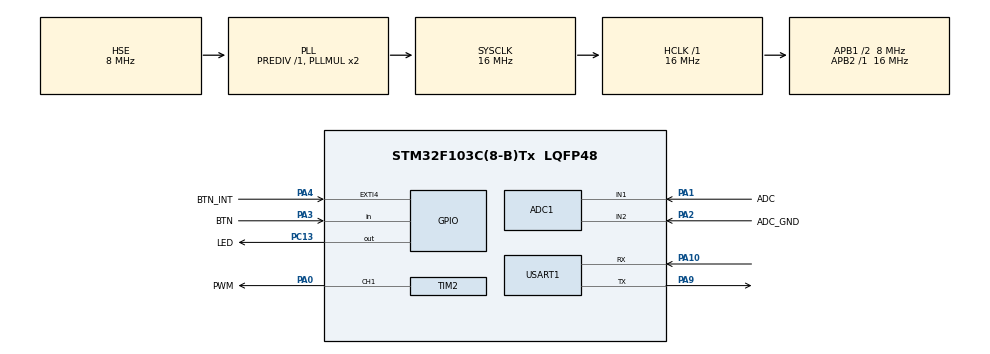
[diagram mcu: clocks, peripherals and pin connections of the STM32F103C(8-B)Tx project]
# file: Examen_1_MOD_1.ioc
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ADC1.Channel-0\#ChannelRegularConversion=ADC_CHANNEL_1
ADC1.NbrOfConversionFlag=1
ADC1.Rank-0\#ChannelRegularConversion=1
ADC1.SamplingTime-0\#ChannelRegularConversion=ADC_SAMPLETIME_1CYCLE_5
ADC1.master=1
Mcu.Family=STM32F1
Mcu.Name=STM32F103C(8-B)Tx
Mcu.Package=LQFP48
NVIC.PriorityGroup=NVIC_PRIORITYGROUP_4
NVIC.TIM2_IRQn=true\:0\:0\:false\:false\:true\:true\:true\:true
PA0-WKUP.GPIO_Label=PWM
PA0-WKUP.Signal=S_TIM2_CH1_ETR
PA1.GPIO_Label=ADC
PA1.Signal=ADCx_IN1
PA10.Mode=Asynchronous
PA10.Signal=USART1_RX
PA13.Mode=Serial_Wire
PA13.Signal=SYS_JTMS-SWDIO
PA14.Mode=Serial_Wire
PA14.Signal=SYS_JTCK-SWCLK
PA2.GPIO_Label=ADC_GND
PA2.Signal=ADCx_IN2
PA3.GPIO_Label=BTN
PA3.GPIO_PuPd=GPIO_PULLUP
PA3.Signal=GPIO_Input
PA4.GPIO_Label=BTN_INT
PA4.GPIO_PuPd=GPIO_PULLUP
PA4.Signal=GPXTI4
PA9.Mode=Asynchronous
PA9.Signal=USART1_TX
PC13-TAMPER-RTC.GPIO_Label=LED
PC13-TAMPER-RTC.Signal=GPIO_Output
PD0-OSC_IN.Mode=HSE-External-Oscillator
PD0-OSC_IN.Signal=RCC_OSC_IN
PD1-OSC_OUT.Mode=HSE-External-Oscillator
PD1-OSC_OUT.Signal=RCC_OSC_OUT
ProjectManager.HeapSize=0x200
ProjectManager.StackSize=0x400
ProjectManager.TargetToolchain=STM32CubeIDE
RCC.AHBFreq_Value=16000000
RCC.APB1CLKDivider=RCC_HCLK_DIV2
RCC.APB1Freq_Value=8000000
RCC.APB1TimFreq_Value=16000000
RCC.APB2Freq_Value=16000000
RCC.APB2TimFreq_Value=16000000
RCC.HCLKFreq_Value=16000000
RCC.PLLSourceVirtual=RCC_PLLSOURCE_HSE
RCC.SYSCLKFreq_VALUE=16000000
RCC.SYSCLKSource=RCC_SYSCLKSOURCE_PLLCLK
RCC.USBFreq_Value=16000000
SH.ADCx_IN1.0=ADC1_IN1,IN1
SH.ADCx_IN2.0=ADC1_IN2,IN2
SH.S_TIM2_CH1_ETR.0=TIM2_CH1,PWM Generation1 CH1
TIM2.AutoReloadPreload=TIM_AUTORELOAD_PRELOAD_ENABLE
TIM2.Channel-PWM\ Generation1\ CH1=TIM_CHANNEL_1
TIM2.Period=1000
TIM2.Prescaler=16-1
TIM2.Pulse-PWM\ Generation1\ CH1=500
USART1.VirtualMode=VM_ASYNC
VP_TIM2_VS_ClockSourceINT.Mode=Internal
board=custom

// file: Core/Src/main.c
/* USER CODE BEGIN Header */
/**
  ******************************************************************************
  * @file           : main.c
  * @brief          : Main program body
  ******************************************************************************
  * @attention
  *
  * Copyright (c) 2026 STMicroelectronics.
  * All rights reserved.
  *
  * This software is licensed under terms that can be found in the LICENSE file
  * in the root directory of this software component.
  * If no LICENSE file comes with this software, it is provided AS-IS.
  *
  ******************************************************************************
  */
/* USER CODE END Header */
#include "main.h"

/* USER CODE BEGIN Includes */
#include "stdio.h"
/* USER CODE END Includes */

/* USER CODE BEGIN PD */

#define MESSAGE_BUFFER_LENGTH (50)

/* USER CODE END PD */

ADC_HandleTypeDef hadc1;

TIM_HandleTypeDef htim2;

UART_HandleTypeDef huart1;

/* USER CODE BEGIN PV */

char msg_buffer[MESSAGE_BUFFER_LENGTH] = {0};

/* USER CODE END PV */

void SystemClock_Config(void);
static void MX_GPIO_Init(void);
static void MX_ADC1_Init(void);
static void MX_TIM2_Init(void);
static void MX_USART1_UART_Init(void);

int main(void)
{

  /* MCU Configuration--------------------------------------------------------*/

  /* Reset of all peripherals, Initializes the Flash interface and the Systick. */
  HAL_Init();

  /* Configure the system clock */
  SystemClock_Config();

  /* Initialize all configured peripherals */
  MX_GPIO_Init();
  MX_ADC1_Init();
  MX_TIM2_Init();
  MX_USART1_UART_Init();
  /* USER CODE BEGIN 2 */

  HAL_Delay(1000);
  HAL_GPIO_WritePin(LED_GPIO_Port, LED_Pin, GPIO_PIN_SET);

//  HAL_TIM_PWM_Start(&htim2, TIM_CHANNEL_1);
  HAL_TIM_PWM_Start_IT(&htim2, TIM_CHANNEL_1);
//  HAL_TIM_Base_Start_IT(&htim2);

//  sniprintf(msg_buffer, MESSAGE_BUFFER_LENGTH, "Test 1 \n\r");
//  HAL_UART_Transmit(&huart1, (const uint8_t*) msg_buffer, MESSAGE_BUFFER_LENGTH, HAL_MAX_DELAY);

  /* USER CODE END 2 */

  /* Infinite loop */
  while (1)
  {

    /* USER CODE BEGIN 3 */

//	  HAL_GPIO_TogglePin(LED_GPIO_Port, LED_Pin);
//	  HAL_UART_Transmit(&huart1, (const uint8_t*) msg_buffer, MESSAGE_BUFFER_LENGTH, HAL_MAX_DELAY);
//	  HAL_Delay(1000);

  }
  /* USER CODE END 3 */
}

void SystemClock_Config(void)
{
  RCC_OscInitTypeDef RCC_OscInitStruct = {0};
  RCC_ClkInitTypeDef RCC_ClkInitStruct = {0};
  RCC_PeriphCLKInitTypeDef PeriphClkInit = {0};

  /** Initializes the RCC Oscillators according to the specified parameters
  * in the RCC_OscInitTypeDef structure.
  */
  RCC_OscInitStruct.OscillatorType = RCC_OSCILLATORTYPE_HSE;
  RCC_OscInitStruct.HSEState = RCC_HSE_ON;
  RCC_OscInitStruct.HSEPredivValue = RCC_HSE_PREDIV_DIV1;
  RCC_OscInitStruct.HSIState = RCC_HSI_ON;
  RCC_OscInitStruct.PLL.PLLState = RCC_PLL_ON;
  RCC_OscInitStruct.PLL.PLLSource = RCC_PLLSOURCE_HSE;
  RCC_OscInitStruct.PLL.PLLMUL = RCC_PLL_MUL2;
  if (HAL_RCC_OscConfig(&RCC_OscInitStruct) != HAL_OK)
  {
    Error_Handler();
  }

  /** Initializes the CPU, AHB and APB buses clocks
  */
  RCC_ClkInitStruct.ClockType = RCC_CLOCKTYPE_HCLK|RCC_CLOCKTYPE_SYSCLK
                              |RCC_CLOCKTYPE_PCLK1|RCC_CLOCKTYPE_PCLK2;
  RCC_ClkInitStruct.SYSCLKSource = RCC_SYSCLKSOURCE_PLLCLK;
  RCC_ClkInitStruct.AHBCLKDivider = RCC_SYSCLK_DIV1;
  RCC_ClkInitStruct.APB1CLKDivider = RCC_HCLK_DIV2;
  RCC_ClkInitStruct.APB2CLKDivider = RCC_HCLK_DIV1;

  if (HAL_RCC_ClockConfig(&RCC_ClkInitStruct, FLASH_LATENCY_0) != HAL_OK)
  {
    Error_Handler();
  }
  PeriphClkInit.PeriphClockSelection = RCC_PERIPHCLK_ADC;
  PeriphClkInit.AdcClockSelection = RCC_ADCPCLK2_DIV2;
  if (HAL_RCCEx_PeriphCLKConfig(&PeriphClkInit) != HAL_OK)
  {
    Error_Handler();
  }
}

static void MX_ADC1_Init(void)
{

  ADC_ChannelConfTypeDef sConfig = {0};

  /** Common config
  */
  hadc1.Instance = ADC1;
  hadc1.Init.ScanConvMode = ADC_SCAN_DISABLE;
  hadc1.Init.ContinuousConvMode = DISABLE;
  hadc1.Init.DiscontinuousConvMode = DISABLE;
  hadc1.Init.ExternalTrigConv = ADC_SOFTWARE_START;
  hadc1.Init.DataAlign = ADC_DATAALIGN_RIGHT;
  hadc1.Init.NbrOfConversion = 1;
  if (HAL_ADC_Init(&hadc1) != HAL_OK)
  {
    Error_Handler();
  }

  /** Configure Regular Channel
  */
  sConfig.Channel = ADC_CHANNEL_1;
  sConfig.Rank = ADC_REGULAR_RANK_1;
  sConfig.SamplingTime = ADC_SAMPLETIME_1CYCLE_5;
  if (HAL_ADC_ConfigChannel(&hadc1, &sConfig) != HAL_OK)
  {
    Error_Handler();
  }

}

static void MX_TIM2_Init(void)
{

  TIM_ClockConfigTypeDef sClockSourceConfig = {0};
  TIM_MasterConfigTypeDef sMasterConfig = {0};
  TIM_OC_InitTypeDef sConfigOC = {0};

  htim2.Instance = TIM2;
  htim2.Init.Prescaler = 16-1;
  htim2.Init.CounterMode = TIM_COUNTERMODE_UP;
  htim2.Init.Period = 1000;
  htim2.Init.ClockDivision = TIM_CLOCKDIVISION_DIV1;
  htim2.Init.AutoReloadPreload = TIM_AUTORELOAD_PRELOAD_ENABLE;
  if (HAL_TIM_Base_Init(&htim2) != HAL_OK)
  {
    Error_Handler();
  }
  sClockSourceConfig.ClockSource = TIM_CLOCKSOURCE_INTERNAL;
  if (HAL_TIM_ConfigClockSource(&htim2, &sClockSourceConfig) != HAL_OK)
  {
    Error_Handler();
  }
  if (HAL_TIM_PWM_Init(&htim2) != HAL_OK)
  {
    Error_Handler();
  }
  sMasterConfig.MasterOutputTrigger = TIM_TRGO_RESET;
  sMasterConfig.MasterSlaveMode = TIM_MASTERSLAVEMODE_DISABLE;
  if (HAL_TIMEx_MasterConfigSynchronization(&htim2, &sMasterConfig) != HAL_OK)
  {
    Error_Handler();
  }
  sConfigOC.OCMode = TIM_OCMODE_PWM1;
  sConfigOC.Pulse = 500;
  sConfigOC.OCPolarity = TIM_OCPOLARITY_HIGH;
  sConfigOC.OCFastMode = TIM_OCFAST_DISABLE;
  if (HAL_TIM_PWM_ConfigChannel(&htim2, &sConfigOC, TIM_CHANNEL_1) != HAL_OK)
  {
    Error_Handler();
  }
  HAL_TIM_MspPostInit(&htim2);

}

static void MX_USART1_UART_Init(void)
{

  huart1.Instance = USART1;
  huart1.Init.BaudRate = 115200;
  huart1.Init.WordLength = UART_WORDLENGTH_8B;
  huart1.Init.StopBits = UART_STOPBITS_1;
  huart1.Init.Parity = UART_PARITY_NONE;
  huart1.Init.Mode = UART_MODE_TX_RX;
  huart1.Init.HwFlowCtl = UART_HWCONTROL_NONE;
  huart1.Init.OverSampling = UART_OVERSAMPLING_16;
  if (HAL_UART_Init(&huart1) != HAL_OK)
  {
    Error_Handler();
  }

}

static void MX_GPIO_Init(void)
{
  GPIO_InitTypeDef GPIO_InitStruct = {0};

  /* GPIO Ports Clock Enable */
  __HAL_RCC_GPIOC_CLK_ENABLE();
  __HAL_RCC_GPIOD_CLK_ENABLE();
  __HAL_RCC_GPIOA_CLK_ENABLE();

  /*Configure GPIO pin Output Level */
  HAL_GPIO_WritePin(LED_GPIO_Port, LED_Pin, GPIO_PIN_RESET);

  /*Configure GPIO pin : LED_Pin */
  GPIO_InitStruct.Pin = LED_Pin;
  GPIO_InitStruct.Mode = GPIO_MODE_OUTPUT_PP;
  GPIO_InitStruct.Pull = GPIO_NOPULL;
  GPIO_InitStruct.Speed = GPIO_SPEED_FREQ_LOW;
  HAL_GPIO_Init(LED_GPIO_Port, &GPIO_InitStruct);

  /*Configure GPIO pin : BTN_Pin */
  GPIO_InitStruct.Pin = BTN_Pin;
  GPIO_InitStruct.Mode = GPIO_MODE_INPUT;
  GPIO_InitStruct.Pull = GPIO_PULLUP;
  HAL_GPIO_Init(BTN_GPIO_Port, &GPIO_InitStruct);

  /*Configure GPIO pin : BTN_INT_Pin */
  GPIO_InitStruct.Pin = BTN_INT_Pin;
  GPIO_InitStruct.Mode = GPIO_MODE_IT_RISING;
  GPIO_InitStruct.Pull = GPIO_PULLUP;
  HAL_GPIO_Init(BTN_INT_GPIO_Port, &GPIO_InitStruct);

}

/* USER CODE BEGIN 4 */

void HAL_TIM_OC_DelayElapsedCallback(TIM_HandleTypeDef *htim) {
	HAL_GPIO_TogglePin(LED_GPIO_Port, LED_Pin);
	if (htim->Instance == TIM2) {
		HAL_GPIO_TogglePin(GPIOA, GPIO_PIN_0);
	}
}

/* USER CODE END 4 */

void Error_Handler(void)
{
  __disable_irq();
  while (1)
  {
  }
}
